# 3067M register map
File version: 1.0
Registers are 32-bit, access per field, reset 0x0 unless marked. A register's access mark holds for its fields unless they carry their own. Offsets are from the block's base; [hi:lo] are bit positions.

## FMC — FMC peripheral interface
Base 0x1C0E0000
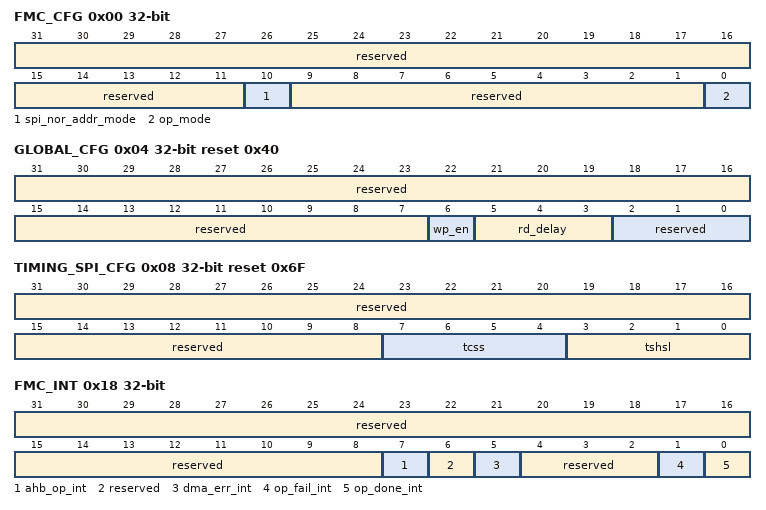
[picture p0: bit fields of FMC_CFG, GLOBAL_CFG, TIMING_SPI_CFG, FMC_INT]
0x00 FMC_CFG — FMC_CFG为器件配置寄存器。
  [31:11] reserved ro — 保留。
  [10] spi_nor_addr_mode rw — SPI地址模式。 0：3Bytes address mode（default）； 1：4Bytes address mode。 复位值由管脚FMC_PAGE_SIZE决定。
  [9:1] reserved ro — 保留。
  [0] op_mode rw — FMC操作模式选择。 0：boot模式； 1：normal模式。
0x04 GLOBAL_CFG reset 0x40 — GLOBAL_CFG为全局配置寄存器。
  [31:7] reserved ro — 保留。
  [6] wp_en rw — 写保护使能（WP管脚）。当使能时，芯片对WP管脚输出为0。 0：不使能； 1：使能。
  [5:3] rd_delay rw — SPI读出数据延迟周期个数（SDR模式下）。 000：读数据延迟0个时钟周期（default）； 001：读数据延迟0.5个器件工作时钟周期； 010：读数据延迟1个器件工作时钟周期； 011：读数据延迟1.5个器件工作时钟周期； 100：读数据延迟2个器件工作时钟周期； 101：读数据延迟2.5个器件工作时钟周期； 110：读数据延迟3个器件工作时钟周期； 111：读数据延迟3.5个器件工作时钟周期。
  [2:0] reserved ro — 保留。
0x08 TIMING_SPI_CFG reset 0x6F — TIMING_SPI_CFG为SPI Timing配置寄存器。
  [31:8] reserved ro — 保留。
  [7:4] tcss rw — CS setup time。 000～111：n+1个接口时钟周期。n为0、1、2、……、7。
  [3:0] tshsl rw — 设置片选的Deselect time，相当于两次Flash操作之间的时间间隔。 0000～1111：n+1个接口时钟周期。n为0、1、2、……、15。
0x18 FMC_INT ro — FMC_INT为中断状态寄存器。
  [31:8] reserved — 保留。
  [7] ahb_op_int — FMC对Flash进行数据操作期间，cpu读写内部Buffer错误中断。 0：无中断； 1：有中断。
  [6] reserved — 保留。
  [5] dma_err_int — DMA传输总线出现错误中断。 0：无中断； 1：有中断。
  [4:2] reserved — 保留。
  [1] op_fail_int — 编程操作失败，上报中断。 0：无中断； 1：有中断。
  [0] op_done_int — FMC本次操作结束中断。 写operation寄存器后，该标志自动清零。 0：无中断； 1：有中断。
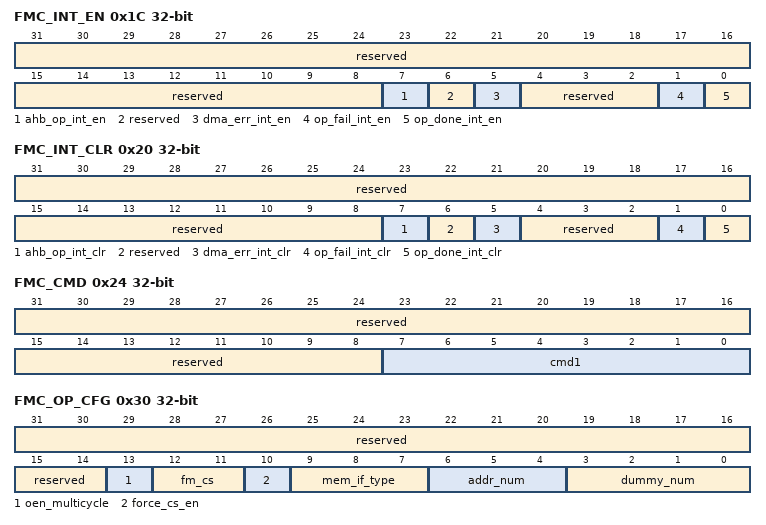
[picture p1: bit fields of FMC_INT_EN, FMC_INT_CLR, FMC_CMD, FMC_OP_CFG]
0x1C FMC_INT_EN — FMC_INT_EN为中断使能寄存器。
  [31:8] reserved ro — 保留。
  [7] ahb_op_int_en rw — FMC读写Flash数据期间，CPU读写内部Buffer错误中断使能。 0：禁止； 1：使能。
  [6] reserved ro — 保留。
  [5] dma_err_int_en rw — DMA传输总线出现错误中断使能。 0：禁止； 1：使能。
  [4:2] reserved ro — 保留。
  [1] op_fail_int_en rw — 编程操作失败中断使能。 0：禁止； 1：使能。
  [0] op_done_int_en rw — FMC本次操作结束中断。 0：禁止； 1：使能。
0x20 FMC_INT_CLR — FMC_INT_CLR为中断清除寄存器。
  [31:8] reserved ro — 保留。
  [7] ahb_op_int_clr wo — 清除ahb_op_err中断，写1清除。
  [6] reserved ro — 保留。
  [5] dma_err_int_clr wo — 清除dma传输总线错误中断，写1清除。
  [4:2] reserved ro — 保留。
  [1] op_fail_int_clr wo — 清除op_fail中断，写1清除。
  [0] op_done_int_clr wo — 清除op_done中断，写1清除。
0x24 FMC_CMD — FMC_CMD为命令字配置寄存器。
  [31:8] reserved ro — 保留。
  [7:0] cmd1 rw — FMC发给SPI NOR Flash的操作命令。
0x2C FMC_ADDRL rw — FMC_ADDRL为器件地址配置寄存器低4Byte。
  [31:0] addrl — 配置Flash器件的操作地址的低4Byte。
0x30 FMC_OP_CFG — FMC_OP_CFG为操作配置寄存器。
  [31:14] reserved ro — 保留。
  [13] oen_multicycle rw — SPI接口读写是对数据线上的oen动态切换时进行dummy cycle的处理。（接口效率高于50M的读操作时必须打开）使能oen_multicycle: 0：不使能； 1：使能。
  [12:11] fm_cs rw — 选择操作的Flash器件。 00：cs0； 01：cs1； 其他：保留。
  [10] force_cs_en rw — cs片选强制使能选择。 0：不使能； 1：使能。
  [9:7] mem_if_type rw — 读操作，SPI Flash接口类型选择。 000：Standard SPI接口类型； 001：Dual-Input/Dual-Output SPI； 010：Dual-I/O SPI； 011：Quad-Input/QUAD-Output SPI； 100：Quad-I/O SPI； 101~111：保留。
  [6:4] addr_num rw — 发给Flash的地址Byte数。
  [3:0] dummy_num rw — 对于dummy_en的操作Byte个数。 （1Byte=4线2时钟周期=2线4时钟周期=1线8时钟周期）
0x34 SPI_OP_ADDR rw — SPI_OP_ADDR为操作地址配置寄存器。
  [31:0] spi_op_addr — 配置SPI NOR Flash的操作地址。每次操作下发器件的操作地址。
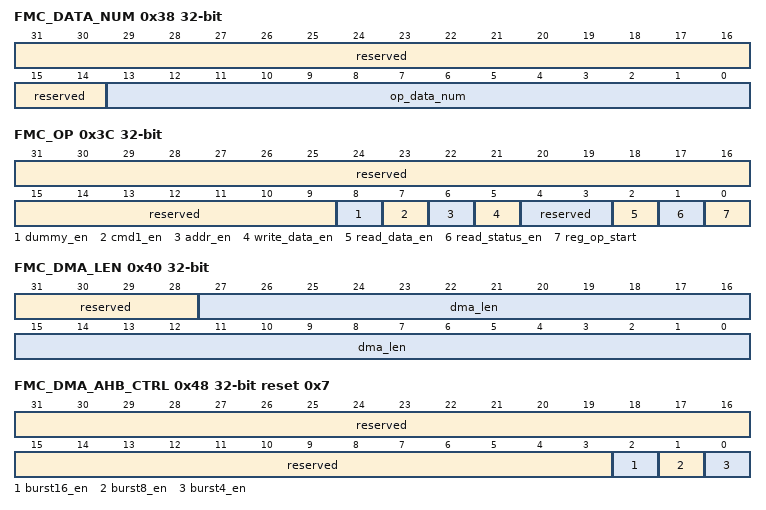
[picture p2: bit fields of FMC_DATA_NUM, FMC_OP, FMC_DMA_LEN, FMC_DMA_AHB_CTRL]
0x38 FMC_DATA_NUM — FMC_DATA_NUM为数据长度寄存器。
  [31:14] reserved ro — 保留。
  [13:0] op_data_num rw — 一次操作所需要处理的数据长度。在有数据传输的操作时需要配置，对于DMA操作或AHB总线直接访问时不需要配置。
0x3C FMC_OP — FMC_OP为操作寄存器。
  [31:9] reserved ro — 保留。
  [8] dummy_en rw — 地址操作后有传输dummy Byte操作使能。 0：禁止； 1：使能。
  [7] cmd1_en rw — 向Flash发command1命令使能。 0：禁止； 1：使能。
  [6] addr_en rw — 向Flash写操作地址使能。 0：禁止； 1：使能。
  [5] write_data_en rw — 向Flash写数据使能。 read_data_en和write_data_en不能同时为1。 0：禁止； 1：使能。
  [4:3] reserved ro — 保留。
  [2] read_data_en rw — 从Flash读数据使能。 read_data_en和write_data_en不能同时为1。 0：禁止； 1：使能。
  [1] read_status_en rw — 向SPI NOR Flash发出读status的05命令，并从对应的Flash读取状态数据，返回的数据写入FMC状态寄存器的fm_status域中，而不写入内部Buffer。 0：禁止； 1：使能。 注意：不能和cmd，addr等使能信号同时有效。
  [0] reg_op_start rw — 操作下发工作使能位。 0：控制器就绪；（软件只能配置为1，使能逻辑。） 1：控制器忙。（逻辑只能配置为0，表示逻辑完成。）
0x40 FMC_DMA_LEN — FMC_DMA_LEN为DMA操作长度寄存器。
  [31:28] reserved ro — 保留。
  [27:0] dma_len rw — DMA操作数据搬运长度，以Byte为单位。
0x48 FMC_DMA_AHB_CTRL reset 0x7 — FMC_DMA_AHB_CTRL为DMA操作控制寄存器。
  [31:3] reserved ro — 保留。
  [2] burst16_en rw — burst16使能。 0：禁止； 1：使能。
  [1] burst8_en rw — burst8使能。 0：禁止； 1：使能。
  [0] burst4_en rw — burst4使能。 0：禁止； 1：使能。
0x4C FMC_DMA_SADDR_D0 rw — FMC_DMA_SADDR_D0为DMA操作SRAM起始地址寄存器0。
  [31:0] dma_mem_saddr_d0 — 指示DMA操作SRAM起始地址寄存器。
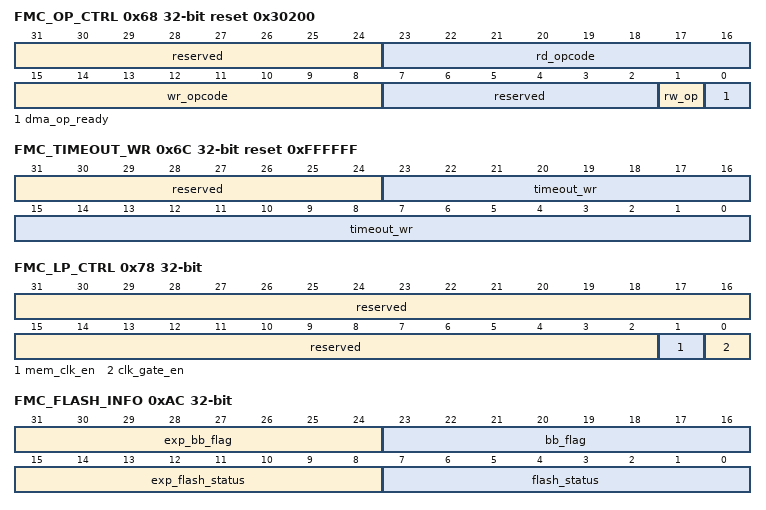
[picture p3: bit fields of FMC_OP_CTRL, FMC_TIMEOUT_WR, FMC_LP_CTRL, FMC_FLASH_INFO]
0x68 FMC_OP_CTRL reset 0x30200 — FMC_OP_CTRL为操作控制寄存器。
  [31:24] reserved ro — 保留。
  [23:16] rd_opcode rw — 非总线方式，DMA读操作命令。（FAST_READ/READ/DUAL_READ）
  [15:8] wr_opcode rw — 非总线方式，DMA写操作命令。
  [7:2] reserved ro — 保留。
  [1] rw_op rw — 下发器件的操作类型。 0：dma读； 1：dma写。
  [0] dma_op_ready rw — 逻辑操作下发使能位。 0：控制器就绪；（控制器自动清零） 1：控制器忙。（由软件配置为1） 软件下发操作时，配置为1，控制器操作完成后将自动清零。软件只能配置1，不能配置0。
0x6C FMC_TIMEOUT_WR reset 0xFFFFFF — FMC_TIMEOUT_WR为写操作TIMEOUT时间寄存器。
  [31:24] reserved ro — 保留。
  [23:0] timeout_wr rw — 编程操作busy等待期间，timeout时间长度。（器件响应超时时间）其单位为1个接口时钟周期。
0x78 FMC_LP_CTRL — FMC_LP_CTRL为低功耗控制寄存器。
  [31:2] reserved ro — 保留。
  [1] mem_clk_en rw — SRAM时钟动态关断选择。 0：不关闭； 1：关断。
  [0] clk_gate_en rw — 时钟门控选择。打开此功能，使用低功耗设计，逻辑选择关闭模块工作时钟。 0：时钟全部使能； 1：根据低功耗设计，关闭时钟。
0xAC FMC_FLASH_INFO ro — FMC_FLASH_INFO为器件状态寄存器值。
  [31:24] exp_bb_flag — 扩展操作下发的只读oob或者读page时，当前页坏块标志对应的未纠错数据。
  [23:16] bb_flag — 只读oob或者读page时，当前页坏块标志对应的未纠错数据。
  [15:8] exp_flash_status — 扩展操作，控制器从器件读状态寄存器值。
  [7:0] flash_status — 器件读状态寄存器值（bit含义详见各Flash器件手册）。
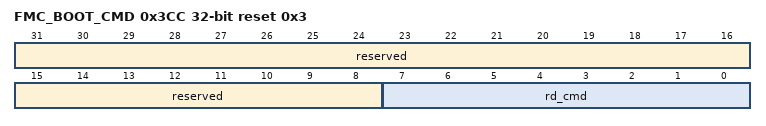
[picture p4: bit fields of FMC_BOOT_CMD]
0x3CC FMC_BOOT_CMD reset 0x3 — FMC_BOOT_CMD为BOOT启动读操作命令配置寄存器。
  [31:8] reserved ro — 保留。
  [7:0] rd_cmd rw — BOOT读操作命令。 0x03：Read（default）； 0x0B：Fast Read，可提频至50M+，需同步配置dummy_num。 其他：保留。
